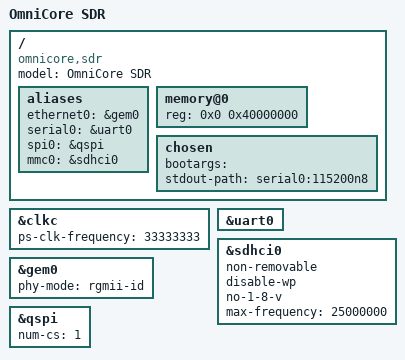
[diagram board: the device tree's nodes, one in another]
// SPDX-License-Identifier: GPL-2.0+
/*
 * OmniCore SDR U-Boot device tree (SPL + U-Boot proper).
 * PS: UART0 on MIO14/15 (FT2232 ch B), SD0 on MIO40-45 via TXS0108 (no CD/WP),
 * GEM0 RGMII MIO16-27 + MDIO MIO52/53 (RTL8211FD-CG),
 * QSPI W25Q256 single SS on MIO1-6, 1 GiB DDR3L (2x MT41K256M16).
 */
/dts-v1/;
#include "zynq-7000.dtsi"

/ {
	model = "OmniCore SDR";
	compatible = "omnicore,sdr", "xlnx,zynq-7000";

	aliases {
		ethernet0 = &gem0;
		serial0 = &uart0;
		spi0 = &qspi;
		mmc0 = &sdhci0;
	};

	memory@0 {
		device_type = "memory";
		reg = <0x0 0x40000000>;
	};

	chosen {
		bootargs = "";
		stdout-path = "serial0:115200n8";
	};
};

&clkc {
	ps-clk-frequency = <33333333>;
};

&uart0 {
	bootph-all;
	status = "okay";
};

&sdhci0 {
	bootph-all;
	status = "okay";
	non-removable;
	disable-wp;
	no-1-8-v;
	max-frequency = <25000000>;	/* TXS0108 level shifter */
};

&gem0 {
	status = "okay";
	phy-mode = "rgmii-id";
};

&qspi {
	bootph-all;
	status = "okay";
	num-cs = <1>;
};
